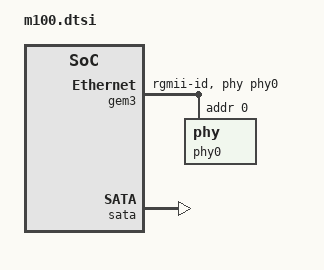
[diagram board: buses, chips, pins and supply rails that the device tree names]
&gem3 {
	status = "okay";
	local-mac-address = [00 0a 35 00 02 90];
	phy-mode = "rgmii-id";
	phy-handle = <&phy0>;
	ge,disable-gigabit = <0x1>;
	phy0: phy@0 {
		reg = <0x0>;
		ti,rx-internal-delay = <0x8>;
		ti,tx-internal-delay = <0xa>;
		ti,fifo-depth = <0x1>;
		max-speed = <100>;
	};
};

&sata {
    status="okay";
};

